# SPI2 register map
Registers from a debugger description file.
Registers are 32-bit, access not given, no defined reset value unless marked. A register's access mark holds for its fields unless they carry their own. Addresses are absolute; registers are grouped by the start of their names; lines under a group give offsets from that group; [hi:lo] are bit positions; {n}, {i} and the like mark numbered series; 'fields as' and 'values as' point back to an identical list; <NAME> marks a mode.

## SPI2
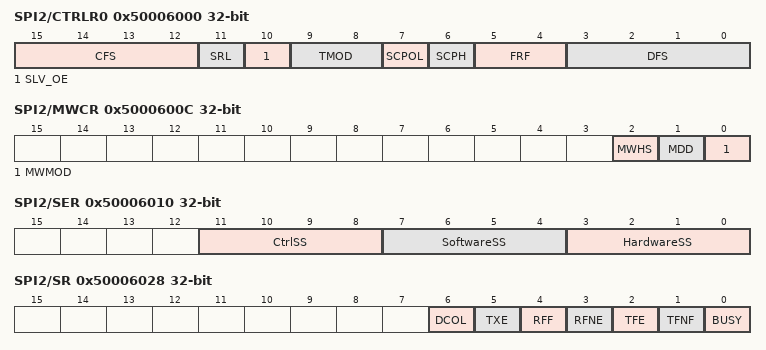
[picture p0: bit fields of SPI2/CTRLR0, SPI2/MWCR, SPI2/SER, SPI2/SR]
0x50006000 SPI2/CTRLR0
  [15:12] CFS, [11] SRL, [10] SLV_OE, [9:8] TMOD, [7] SCPOL, [6] SCPH, [5:4] FRF, [3:0] DFS
0x50006004 SPI2/CTRLR1
  [15:0] NDF
0x50006008 SPI2/SSIENR
  [0] SSIENR
0x5000600C SPI2/MWCR
  [2] MWHS, [1] MDD, [0] MWMOD
0x50006010 SPI2/SER
  [11:8] CtrlSS, [7:4] SoftwareSS, [3:0] HardwareSS
0x50006014 SPI2/BAUDR
  [15:0] SCKDV
0x50006018 SPI2/TXFTLR
  [3:0] TFT
0x5000601C SPI2/RXFTLR
  [3:0] RFT
0x50006020 SPI2/TXFLR ro
  [3:0] TXTFL
0x50006024 SPI2/RXFLR ro
  [3:0] RXTFL
0x50006028 SPI2/SR ro
  [6] DCOL, [5] TXE, [4] RFF, [3] RFNE, [2] TFE, [1] TFNF, [0] BUSY
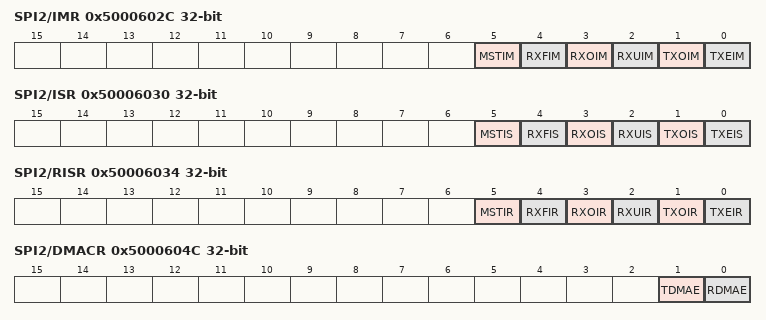
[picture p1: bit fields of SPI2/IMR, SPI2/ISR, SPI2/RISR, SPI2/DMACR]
0x5000602C SPI2/IMR
  [5] MSTIM, [4] RXFIM, [3] RXOIM, [2] RXUIM, [1] TXOIM, [0] TXEIM
0x50006030 SPI2/ISR ro
  [5] MSTIS, [4] RXFIS, [3] RXOIS, [2] RXUIS, [1] TXOIS, [0] TXEIS
0x50006034 SPI2/RISR ro
  [5] MSTIR, [4] RXFIR, [3] RXOIR, [2] RXUIR, [1] TXOIR, [0] TXEIR
0x50006038 SPI2/TXOICR ro
  [0] TXOICR
0x5000603C SPI2/RXOICR ro
  [0] RXOICR
0x50006040 SPI2/RXUICR ro
  [0] RXUICR
0x50006044 SPI2/MSTICR ro
  [0] MSTICR
0x50006048 SPI2/ICR ro
  [0] ICR
0x5000604C SPI2/DMACR
  [1] TDMAE, [0] RDMAE
0x50006050 SPI2/DMATDLR
  [3:0] DMATDLR
0x50006054 SPI2/DMARDLR
  [3:0] DMARDLR
0x50006058 SPI2/IDR ro
  [31:0] ICR
0x5000605C SPI2/SSI_COMP_VERSION ro
0x50006060 SPI2/DR
  [15:0] DR
0x500060F0 SPI2/RX_SAMPLE_DLY
  [7:0] RX_Sample_Delay
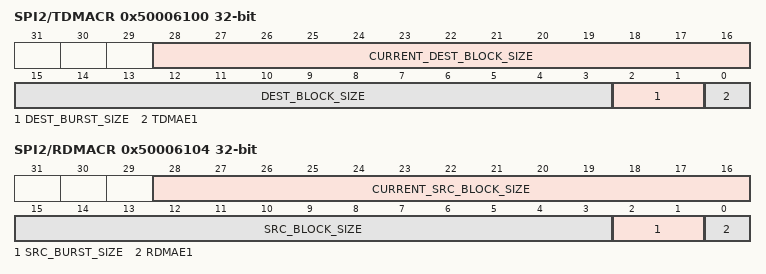
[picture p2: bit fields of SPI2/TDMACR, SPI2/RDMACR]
0x50006100 SPI2/TDMACR
  [28:16] CURRENT_DEST_BLOCK_SIZE, [15:3] DEST_BLOCK_SIZE, [2:1] DEST_BURST_SIZE, [0] TDMAE1
0x50006104 SPI2/RDMACR
  [28:16] CURRENT_SRC_BLOCK_SIZE, [15:3] SRC_BLOCK_SIZE, [2:1] SRC_BURST_SIZE, [0] RDMAE1
